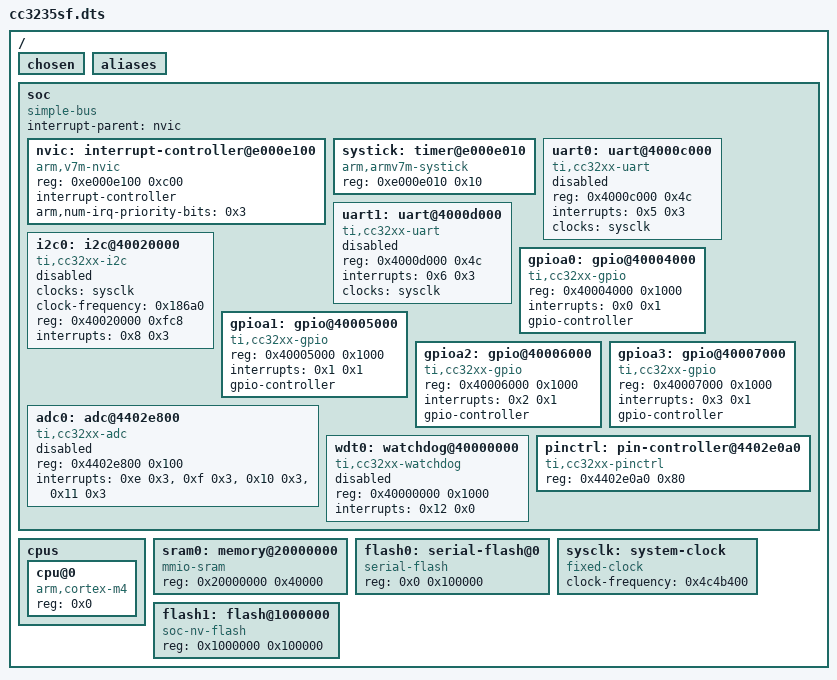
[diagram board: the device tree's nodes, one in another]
/dts-v1/;

/ {
	#address-cells = < 0x1 >;
	#size-cells = < 0x1 >;
	chosen {
	};
	aliases {
	};
	soc {
		#address-cells = < 0x1 >;
		#size-cells = < 0x1 >;
		compatible = "simple-bus";
		interrupt-parent = < &nvic >;
		ranges;
		nvic: interrupt-controller@e000e100 {
			#address-cells = < 0x1 >;
			compatible = "arm,v7m-nvic";
			reg = < 0xe000e100 0xc00 >;
			interrupt-controller;
			#interrupt-cells = < 0x2 >;
			arm,num-irq-priority-bits = < 0x3 >;
			phandle = < 0x1 >;
		};
		systick: timer@e000e010 {
			compatible = "arm,armv7m-systick";
			reg = < 0xe000e010 0x10 >;
		};
		uart0: uart@4000c000 {
			compatible = "ti,cc32xx-uart";
			reg = < 0x4000c000 0x4c >;
			interrupts = < 0x5 0x3 >;
			clocks = < &sysclk >;
			status = "disabled";
		};
		uart1: uart@4000d000 {
			compatible = "ti,cc32xx-uart";
			reg = < 0x4000d000 0x4c >;
			interrupts = < 0x6 0x3 >;
			clocks = < &sysclk >;
			status = "disabled";
		};
		i2c0: i2c@40020000 {
			compatible = "ti,cc32xx-i2c";
			clocks = < &sysclk >;
			clock-frequency = < 0x186a0 >;
			#address-cells = < 0x1 >;
			#size-cells = < 0x0 >;
			reg = < 0x40020000 0xfc8 >;
			interrupts = < 0x8 0x3 >;
			status = "disabled";
		};
		gpioa0: gpio@40004000 {
			compatible = "ti,cc32xx-gpio";
			reg = < 0x40004000 0x1000 >;
			interrupts = < 0x0 0x1 >;
			gpio-controller;
			#gpio-cells = < 0x2 >;
		};
		gpioa1: gpio@40005000 {
			compatible = "ti,cc32xx-gpio";
			reg = < 0x40005000 0x1000 >;
			interrupts = < 0x1 0x1 >;
			gpio-controller;
			#gpio-cells = < 0x2 >;
		};
		gpioa2: gpio@40006000 {
			compatible = "ti,cc32xx-gpio";
			reg = < 0x40006000 0x1000 >;
			interrupts = < 0x2 0x1 >;
			gpio-controller;
			#gpio-cells = < 0x2 >;
		};
		gpioa3: gpio@40007000 {
			compatible = "ti,cc32xx-gpio";
			reg = < 0x40007000 0x1000 >;
			interrupts = < 0x3 0x1 >;
			gpio-controller;
			#gpio-cells = < 0x2 >;
		};
		adc0: adc@4402e800 {
			compatible = "ti,cc32xx-adc";
			reg = < 0x4402e800 0x100 >;
			interrupts = < 0xe 0x3 >, < 0xf 0x3 >, < 0x10 0x3 >, < 0x11 0x3 >;
			status = "disabled";
			#io-channel-cells = < 0x1 >;
		};
		wdt0: watchdog@40000000 {
			compatible = "ti,cc32xx-watchdog";
			reg = < 0x40000000 0x1000 >;
			interrupts = < 0x12 0x0 >;
			status = "disabled";
		};
		pinctrl: pin-controller@4402e0a0 {
			compatible = "ti,cc32xx-pinctrl";
			reg = < 0x4402e0a0 0x80 >;
		};
	};
	cpus {
		#address-cells = < 0x1 >;
		#size-cells = < 0x0 >;
		cpu@0 {
			device_type = "cpu";
			compatible = "arm,cortex-m4";
			reg = < 0x0 >;
		};
	};
	sram0: memory@20000000 {
		compatible = "mmio-sram";
		reg = < 0x20000000 0x40000 >;
	};
	flash0: serial-flash@0 {
		compatible = "serial-flash";
		reg = < 0x0 0x100000 >;
	};
	sysclk: system-clock {
		compatible = "fixed-clock";
		clock-frequency = < 0x4c4b400 >;
		#clock-cells = < 0x0 >;
		phandle = < 0x2 >;
	};
	flash1: flash@1000000 {
		compatible = "soc-nv-flash";
		reg = < 0x1000000 0x100000 >;
	};
};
